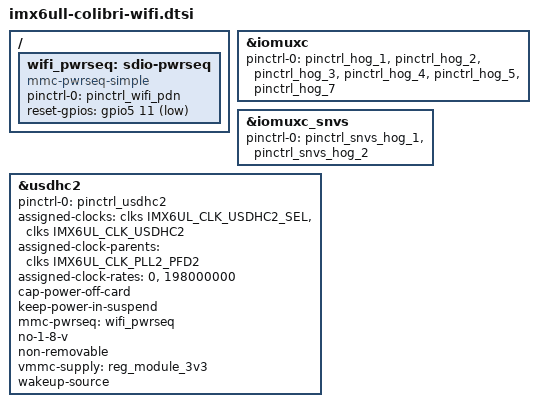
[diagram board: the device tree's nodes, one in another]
/*
 * Copyright (C) 2017 Toradex AG
 *
 * This program is free software; you can redistribute it and/or modify
 * it under the terms of the GNU General Public License version 2 as
 * published by the Free Software Foundation.
 */

#include "imx6ull-colibri.dtsi"

/ {

	wifi_pwrseq: sdio-pwrseq {
		compatible = "mmc-pwrseq-simple";
		pinctrl-names = "default";
		pinctrl-0 = <&pinctrl_wifi_pdn>;
		reset-gpios = <&gpio5 11 GPIO_ACTIVE_LOW>;
	};
};

&iomuxc {
	pinctrl-names = "default";
	pinctrl-0 = <&pinctrl_hog_1 &pinctrl_hog_2 &pinctrl_hog_3
		&pinctrl_hog_4 &pinctrl_hog_5 &pinctrl_hog_7>;

};

&iomuxc_snvs {
	pinctrl-names = "default";
	pinctrl-0 = <&pinctrl_snvs_hog_1 &pinctrl_snvs_hog_2>;
};

&usdhc2 {
	pinctrl-names = "default";
	pinctrl-0 = <&pinctrl_usdhc2>;
	assigned-clocks = <&clks IMX6UL_CLK_USDHC2_SEL>, <&clks IMX6UL_CLK_USDHC2>;
	assigned-clock-parents = <&clks IMX6UL_CLK_PLL2_PFD2>;
	assigned-clock-rates = <0>, <198000000>;
	cap-power-off-card;
	keep-power-in-suspend;
	mmc-pwrseq = <&wifi_pwrseq>;
	no-1-8-v;
	non-removable;
	vmmc-supply = <&reg_module_3v3>;
	wakeup-source;
	status = "okay";
};
